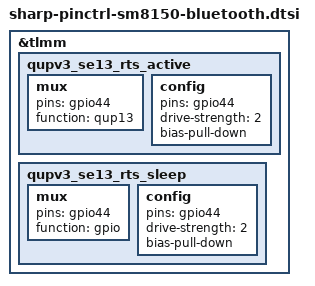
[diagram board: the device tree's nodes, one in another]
/* Copyright (c) 2017-2018, The Linux Foundation. All rights reserved.
 *
 * This program is free software; you can redistribute it and/or modify
 * it under the terms of the GNU General Public License version 2 and
 * only version 2 as published by the Free Software Foundation.
 *
 * This program is distributed in the hope that it will be useful,
 * but WITHOUT ANY WARRANTY; without even the implied warranty of
 * MERCHANTABILITY or FITNESS FOR A PARTICULAR PURPOSE.  See the
 * GNU General Public License for more details.
 */

/*-----------------------------------------*/
/* Add SHARP pin mappings.                 */
/*-----------------------------------------*/
&tlmm {
	/*****************************************/
	/*  UART/Serial                          */
	/*****************************************/
	/* UART 13 */
	qupv3_se13_rts_active: qupv3_se13_rts_active {
		mux {
			pins = "gpio44";
			function = "qup13";
		};
		config {
			pins = "gpio44";
			drive-strength = <2>;
			bias-pull-down;
		};
	};

	qupv3_se13_rts_sleep: qupv3_se13_rts_sleep {
		mux {
			pins = "gpio44";
			function = "gpio";
		};
		config {
			pins = "gpio44";
			drive-strength = <2>;
			bias-pull-down;
		};
	};
};
